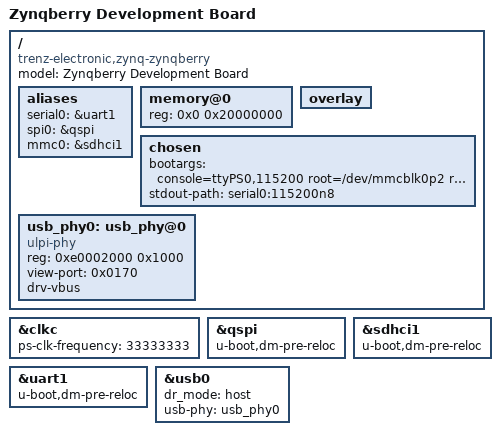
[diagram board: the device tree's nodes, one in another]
/*
 * Digilent ZYBO board DTS
 *
 *  Copyright (C) 2011 - 2015 Xilinx
 *  Copyright (C) 2012 National Instruments Corp.
 *
 * SPDX-License-Identifier:	GPL-2.0+
 */
/dts-v1/;
/include/ "zynq-7000.dtsi"

/ {
	model = "Zynqberry Development Board";
	compatible = "trenz-electronic,zynq-zynqberry", "xlnx,zynq-7000";

	aliases {
		serial0 = &uart1;
		spi0 = &qspi;
		mmc0 = &sdhci1;
	};

	memory@0 {
		device_type = "memory";
		reg = <0x0 0x20000000>;
	};

	overlay {

	};

	chosen {
		bootargs = "console=ttyPS0,115200 root=/dev/mmcblk0p2 rw rootwait earlyprintk earlycon";
		stdout-path = "serial0:115200n8";
	};

        usb_phy0: usb_phy@0 {
		compatible = "ulpi-phy";
		#phy-cells = <0>;
		reg = <0xe0002000 0x1000>;
		view-port = <0x0170>;
		drv-vbus;
        };
};

&clkc {
	ps-clk-frequency = <33333333>;
};

&qspi {
	u-boot,dm-pre-reloc;
	status = "okay";
};

&sdhci1 {
	u-boot,dm-pre-reloc;
	status = "okay";
};

&uart1 {
	u-boot,dm-pre-reloc;
	status = "okay";
};

&usb0 {
	status = "okay";
	dr_mode = "host";
	usb-phy = <&usb_phy0>;
};

